# MCXA133 register map
Vendor: nxp.com; File version: 1.0
CPU: CM33 r2p0, little endian, no MPU, no FPU, VTOR, 3 interrupt priority bits
Registers are 32-bit, read-write, reset 0x0 unless marked. A register's access mark holds for its fields unless they carry their own. Offsets are from the block's base; [hi:lo] are bit positions; {n}, {i} and the like mark numbered series; 'fields as' and 'values as' point back to an identical list.

## ADC0 — ADC
Base 0x400AF000
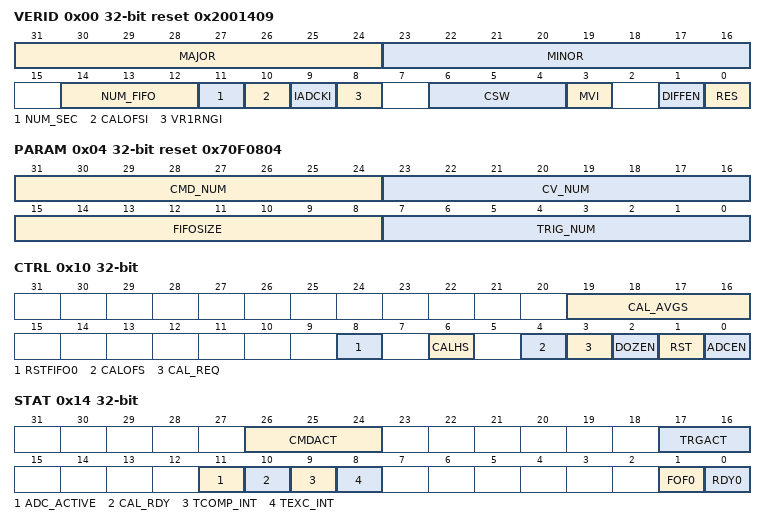
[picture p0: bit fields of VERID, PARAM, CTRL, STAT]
0x00 VERID ro reset 0x2001409 — Version ID Register
  [31:24] MAJOR — Major Version Number
  [23:16] MINOR — Minor Version Number
  [14:12] NUM_FIFO — Number of FIFOs
    0=NO_FIFO_IMPLEMENTED (N/A); 1=CNT_1 (This design supports one result FIFO.); 2=CNT_2 (This design supports two result FIFOs.); 3=CNT_3 (This design supports three result FIFOs.); 4=CNT_4 (This design supports four result FIFOs.)
  [11] NUM_SEC — Number of Single Ended Outputs Supported
    0=SINGLE_CONVERTOR (This design supports one single ended conversion at a time.); 1=DUAL_CONVERTOR (This design supports two simultaneous single ended conversions.)
  [10] CALOFSI — Calibration Function Implemented
    0=CAL_FUNCTION_NOT_AVAILABLE (Calibration Not Implemented.); 1=CAL_FUNCTION_AVAILABLE (Calibration Implemented.)
  [9] IADCKI — Internal ADC Clock Implemented
    0=INTERNAL_CLK_NOT_AVAILABLE (Internal clock source not implemented.); 1=INTERNAL_CLK_AVAILABLE (Internal clock source (and CFG[ADCKEN]) implemented.)
  [8] VR1RNGI — Voltage Reference 1 Range Control Bit Implemented
    0=REF1_FIXED_VOLTAGE_RANGE (Range control not required. CFG[VREF1RNG] is not implemented.); 1=REF1_SELECTABLE_VOLTAGE_RANGE (Range control required. CFG[VREF1RNG] is implemented.)
  [6:4] CSW — Channel Scale Width
    0=CSCALE_NOT_SUPPORTED (Channel scaling not supported.); 1=BIT_WIDTH_1 (Channel scaling supported. 1-bit CSCALE control field.); 6=BIT_WIDTH_6 (Channel scaling supported. 6-bit CSCALE control field.)
  [3] MVI — Multi Vref Implemented
    0=MULTIPLE_REF_NOT_SUPPORTED (Single voltage reference high (VREFH) input supported.); 1=MULTIPLE_REF_SUPPORTED (Multiple voltage reference high (VREFH) inputs supported.)
  [1] DIFFEN — Differential Supported
    0=DIFFERENTIAL_NOT_SUPPORTED (Differential operation not supported.); 1=DIFFERENTIAL_SUPPORTED (Differential operation supported.)
  [0] RES — Resolution
    0=MAX_13_bit (Up to 12-bit single ended resolution supported (and 13-bit differential resolution if VERID[DIFFEN] = 1b).); 1=MAX_16_bit (Up to 16-bit single ended resolution supported (and 16-bit differential resolution if VERID[DIFFEN] = 1b).)
0x04 PARAM ro reset 0x70F0804 — Parameter Register
  [31:24] CMD_NUM — Command Buffer Number
  [23:16] CV_NUM — Compare Value Number
  [15:8] FIFOSIZE — Result FIFO Depth
    1=ENTRIES_2 (Result FIFO depth = 2 dataword.); 4=ENTRIES_4 (Result FIFO depth = 4 datawords.); 8=ENTRIES_8 (Result FIFO depth = 8 datawords.); 16=ENTRIES_16 (Result FIFO depth = 16 datawords.); 32=ENTRIES_32 (Result FIFO depth = 32 datawords.); 64=ENTRIES_64 (Result FIFO depth = 64 datawords.)
  [7:0] TRIG_NUM — Trigger Number
0x10 CTRL — Control Register
  [19:16] CAL_AVGS — Auto-Calibration Averages
    0=NO_AVERAGE (Single conversion.); 1=AVERAGE_2 (2 conversions averaged.); 2=AVERAGE_4 (4 conversions averaged.); 3=AVERAGE_8 (8 conversions averaged.); 4=AVERAGE_16 (16 conversions averaged.); 5=AVERAGE_32 (32 conversions averaged.); 6=AVERAGE_64 (64 conversions averaged.); 7=AVERAGE_128 (128 conversions averaged.); 8=AVERAGE_256 (256 conversions averaged.); 9=AVERAGE_512 (512 conversions averaged.); 10=AVERAGE_1024 (1024 conversions averaged.)
  [8] RSTFIFO0 — Reset FIFO 0
    0=NO_ACTION (No effect.); 1=TRIGGER_RESET (FIFO 0 is reset.)
  [6] CALHS — High Speed Mode Trim Request
    0=NO_ACTIVE_HS_TRIM_REQUEST (No request for high speed mode trim has been made); 1=HS_TRIM_REQUEST_PENDING (Request for high speed mode trim has been made)
  [4] CALOFS — Offset Calibration Request
    0=NO_ACTIVE_OFFSET_CALIBRATION_REQUEST (No request for offset calibration has been made); 1=OFFSET_CALIBRATION_REQUEST_PENDING (Request for offset calibration function)
  [3] CAL_REQ — Auto-Calibration Request
    0=NO_CALIBRATION_REQUEST (No request for hardware calibration has been made); 1=CALIBRATION_REQUEST_PENDING (A request for hardware calibration has been made)
  [2] DOZEN — Doze Enable
    0=ENABLED (ADC is enabled in low power mode.); 1=DISABLED (ADC is disabled in low power mode.)
  [1] RST — Software Reset
    0=RELEASED_FROM_RESET (ADC logic is not reset.); 1=HELD_IN_RESET (ADC logic is reset.)
  [0] ADCEN — ADC Enable
    0=DISABLED (ADC is disabled.); 1=ENABLED (ADC is enabled.)
0x14 STAT — Status Register
  [26:24] CMDACT ro — Command Active
    0=NO_COMMAND_ACTIVE (No command is currently in progress.); 1=COMMAND_1 (Command 1 currently being executed.); 2=COMMAND_2 (Command 2 currently being executed.); {v}=COMMAND_x_{v} (Associated command number is currently being executed.) (v=3..7)
  [17:16] TRGACT ro — Trigger Active
    {v}=TRIG_{v} (Command (sequence) associated with Trigger {v} currently being executed.) (v=0..3)
  [11] ADC_ACTIVE ro
    0=NOT_ACTIVE (The ADC is IDLE. There are no pending triggers to service and no active commands are being processed.); 1=BUSY (The ADC is processing a conversion, running through the power up delay, or servicing a trigger.)
  [10] CAL_RDY ro — Calibration Ready
    0=NOT_SET (Calibration is incomplete or hasn't been ran.); 1=HARDWARE_CAL_STEP_COMPLETED (The ADC is calibrated.)
  [9] TCOMP_INT write-1-clears — Interrupt Flag For Trigger Completion
    0=FLAG_CLEAR (Either IE[TCOMP_IE] is set to 0, or no trigger sequences have run to completion.); 1=COMPLETION_DETECTED (Trigger sequence has been completed and all data is stored in the associated FIFO.)
  [8] TEXC_INT write-1-clears — Interrupt Flag For High Priority Trigger Exception
    0=NO_EXCEPTION (No trigger exceptions have occurred.); 1=EXCEPTION_DETECTED (A trigger exception has occurred and is pending acknowledgement.)
  [1] FOF0 write-1-clears — Result FIFO 0 Overflow Flag
    0=NO_OVERFLOW (No result FIFO 0 overflow has occurred since the last time the flag was cleared.); 1=OVERFLOW_DETECTED (At least one result FIFO 0 overflow has occurred since the last time the flag was cleared.)
  [0] RDY0 ro — Result FIFO 0 Ready Flag
    0=BELOW_THRESHOLD (Result FIFO 0 data level not above watermark level.); 1=ABOVE_THRESHOLD (Result FIFO 0 holding data above watermark level.)
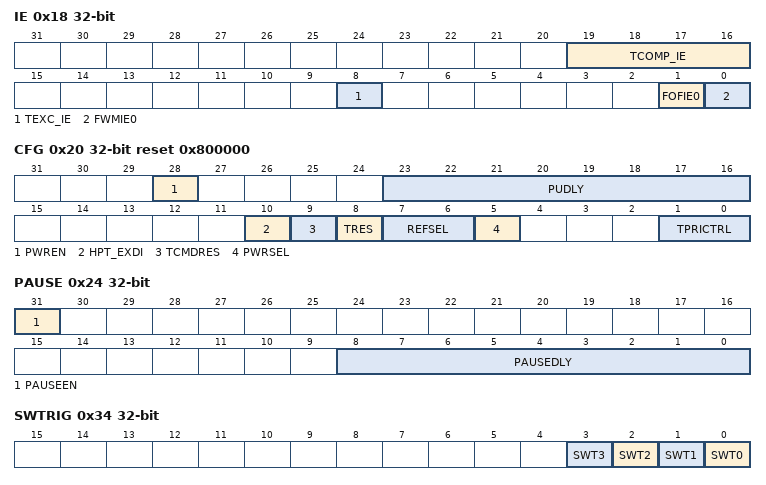
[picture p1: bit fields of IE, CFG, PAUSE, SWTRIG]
0x18 IE — Interrupt Enable Register
  [19:16] TCOMP_IE — Trigger Completion Interrupt Enable
    0=DISABLED (Trigger completion interrupts are disabled.); 1=TRIGGER_0_COMPLETE_ENABLED (Trigger completion interrupts are enabled for trigger source 0 only.); 2=TRIGGER_1_COMPLETE_ENABLED (Trigger completion interrupts are enabled for trigger source 1 only.); {v}=TRIGGER_x_COMPLETE_ENABLED_{v} (Associated trigger completion interrupts are enabled.) (v=3..14); 15=ALL_TRIGGER_COMPLETES_ENABLED (Trigger completion interrupts are enabled for every trigger source.)
  [8] TEXC_IE — Trigger Exception Interrupt Enable
    0=DISABLED (Trigger exception interrupts are disabled.); 1=ENABLED (Trigger exception interrupts are enabled.)
  [1] FOFIE0 — Result FIFO 0 Overflow Interrupt Enable
    0=DISABLED (FIFO 0 overflow interrupts are not enabled.); 1=ENABLED (FIFO 0 overflow interrupts are enabled.)
  [0] FWMIE0 — FIFO 0 Watermark Interrupt Enable
    0=DISABLED (FIFO 0 watermark interrupts are not enabled.); 1=ENABLED (FIFO 0 watermark interrupts are enabled.)
0x1C DE — DMA Enable Register
  [0] FWMDE0 — FIFO 0 Watermark DMA Enable
    0=DISABLED (DMA request disabled.); 1=ENABLED (DMA request enabled.)
0x20 CFG reset 0x800000 — Configuration Register
  [28] PWREN — ADC Analog Pre-Enable
    0=NOT_PRE_ENABLED (ADC analog circuits are only enabled while conversions are active. Performance is affected due to analog startup delays.); 1=PRE_ENABLED (ADC analog circuits are pre-enabled and ready to execute conversions without startup delays (at the cost of higher DC current consumption). Note that a single power up delay (CFG[PUDLY]) is executed immediately once PWREN is set, and any detected trigger does not begin ADC operation until the power up delay time has passed. After this initial delay expires the analog remains pre-enabled and no additional delays are executed.)
  [23:16] PUDLY — Power Up Delay
  [10] HPT_EXDI — High Priority Trigger Exception Disable
    0=ENABLED (High priority trigger exceptions are enabled.); 1=DISABLED (High priority trigger exceptions are disabled.)
  [9] TCMDRES — Trigger Command Resume
    0=DISABLED (Trigger sequences interrupted by a high priority trigger exception is automatically restarted.); 1=ENABLED (Trigger sequences interrupted by a high priority trigger exception is resumed from the command executing before the exception.)
  [8] TRES — Trigger Resume Enable
    0=DISABLED (Trigger sequences interrupted by a high priority trigger exception are not automatically resumed or restarted.); 1=ENABLED (Trigger sequences interrupted by a high priority trigger exception are automatically resumed or restarted.)
  [7:6] REFSEL — Voltage Reference Selection
    0=OPTION_1 ((Default) Option 1 setting.); 1=OPTION_2 (Option 2 setting.); 2=OPTION_3 (Option 3 setting.)
  [5] PWRSEL — Power Configuration Select
    0=LOWEST (Low power); 1=HIGHEST (High power)
  [1:0] TPRICTRL — ADC Trigger Priority Control
    0=ABORT_CURRENT_ON_PRIORITY (If a higher priority trigger is detected during command processing, the current conversion is aborted and the new command specified by the trigger is started.); 1=FINISH_CURRENT_ON_PRIORITY (If a higher priority trigger is received during command processing, the current command is stopped after completing the current conversion. If averaging is enabled, the averaging loop will be completed. However, CMDHa[LOOP] will be ignored and the higher priority trigger will be serviced.); 2=FINISH_SEQUENCE_ON_PRIORITY (If a higher priority trigger is received during command processing, the current command will be completed (averaging, looping, compare) before servicing the higher priority trigger.)
0x24 PAUSE
  [31] PAUSEEN — PAUSE Option Enable
    0=DISABLED (Pause operation disabled); 1=ENABLED (Pause operation enabled)
  [8:0] PAUSEDLY — Pause Delay
0x34 SWTRIG — Software Trigger Register
  [n] SWT{n} (n=0..3) — Software Trigger {n} Event
    0=NO_TRIGGER (No trigger {n} event generated.); 1=INITIATE_TRIGGER_{n} (Trigger {n} event generated.)
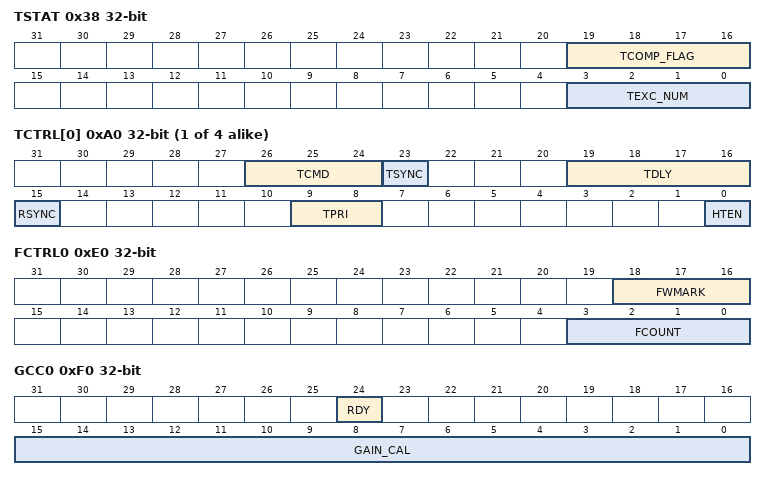
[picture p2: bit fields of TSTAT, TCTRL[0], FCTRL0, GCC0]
0x38 TSTAT write-1-clears — Trigger Status Register
  [19:16] TCOMP_FLAG write-1-clears — Trigger Completion Flag
    0=NO_TRIGGER (No triggers have been completed. Trigger completion interrupts are disabled.); 1=BIT0_MEANS_TRIGGER_0_COMPLETED (Trigger 0 has been completed and trigger 0 has enabled completion interrupts.); 2=BIT1_MEANS_TRIGGER_1_COMPLETED (Trigger 1 has been completed and trigger 1 has enabled completion interrupts.); {v}=SET_BITS_INDICATE_TRIGGER_x_COMPLETED_{v} (Associated trigger sequence has completed and has enabled completion interrupts.) (v=3..14); 15=ALL_BITS_SET_INDICATE_ALL_TRIGGERS_COMPLETED (Every trigger sequence has been completed and every trigger has enabled completion interrupts.)
  [3:0] TEXC_NUM write-1-clears — Trigger Exception Number
    0=NO_EXCEPTIONS (No triggers have been interrupted by a high priority exception. Or CFG[TRES] = 1.); 1=BIT0_MEANS_TRIGGER_0_INTERRUPTED (Trigger 0 has been interrupted by a high priority exception.); 2=BIT1_MEANS_TRIGGER_1_INTERRUPTED (Trigger 1 has been interrupted by a high priority exception.); {v}=SET_BITS_INDICATE_TRIGGER_x_INTERRUPTED_{v} (Associated trigger sequence has interrupted by a high priority exception.) (v=3..14); 15=ALL_BITS_SET_INDICATE_ALL_TRIGGERS_INTERRUPTED (Every trigger sequence has been interrupted by a high priority exception.)
0x40 OFSTRIM — Offset Trim Register
  [9:0] OFSTRIM — Trim for Offset
0x48 HSTRIM — High Speed Trim Register
  [4:0] HSTRIM — Trim for High Speed Conversions
{0xA0+4i} TCTRL[{i}] (i=0..3) — Trigger Control Register
  [26:24] TCMD — Trigger Command Select
    0=NOT_VALID (Not a valid selection from the command buffer. Trigger event is ignored.); 1=EXECUTE_CMD1 (CMD1 is executed); {v}=EXECUTE_CORRESPONDING_CMD_{v} (Corresponding CMD is executed) (v=2..6); 7=EXECUTE_CMD7 (CMD7 is executed)
  [23] TSYNC — Trigger Synchronous Select
  [19:16] TDLY — Trigger Delay Select
  [15] RSYNC — Trigger Resync
  [9:8] TPRI — Trigger Priority Setting
    0=HIGHEST_PRIORITY (Set to highest priority, Level 1); 1=CORRESPONDING_LOWER_PRIORITY_1 (Set to corresponding priority level); 2=CORRESPONDING_LOWER_PRIORITY_2 (Set to corresponding priority level); 3=LOWEST_PRIORITY (Set to lowest priority, Level 4)
  [0] HTEN — Trigger Enable
    0=DISABLED (Hardware trigger source disabled); 1=ENABLED (Hardware trigger source enabled)
0xE0 FCTRL0 — FIFO Control Register
  [18:16] FWMARK — Watermark Level Selection
  [3:0] FCOUNT ro — Result FIFO Counter
0xF0 GCC0 ro — Gain Calibration Control
  [24] RDY — Gain Calibration Value Valid
    0=GAIN_CAL_NOT_VALID (The GAIN_CAL value is invalid. Run the hardware calibration routine for this value to be set.); 1=HARDWARE_CAL_ROUTINE_COMPLETED (The GAIN_CAL value is valid. GAIN_CAL should be used by software to derive GCRa[GCALR].)
  [15:0] GAIN_CAL — Gain Calibration Value
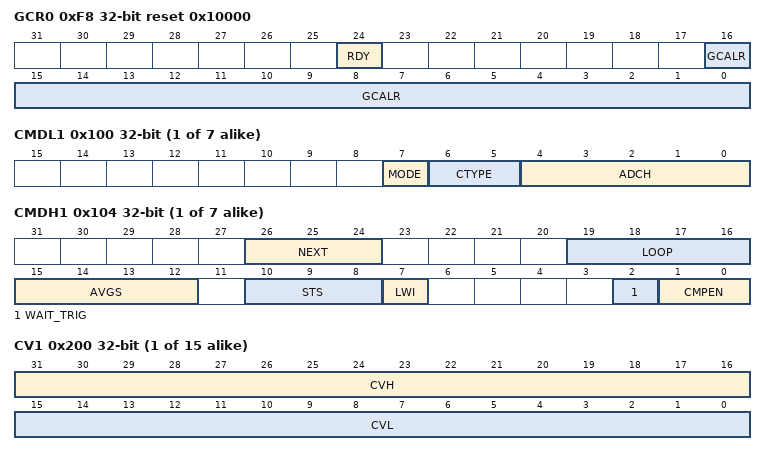
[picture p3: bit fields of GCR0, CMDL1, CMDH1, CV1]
0xF8 GCR0 reset 0x10000 — Gain Calculation Result
  [24] RDY — Gain Calculation Ready
    0=NOT_VALID (The GCALR value is invalid.); 1=VALID (The GCALR value is valid.)
  [16:0] GCALR — Gain Calculation Result
{0xF8+8i} CMDL{i} (i=1..7) — Command Low Buffer Register
  [7] MODE — Select Resolution of Conversions
    0=DATA_12_BITS (Standard resolution. Single-ended 12-bit conversion.); 1=DATA_16_BITS (High resolution. Single-ended 16-bit conversion.)
  [6:5] CTYPE ro — Conversion Type
    0=SINGLE_ENDED_A_SIDE_CHANNEL (Single-Ended Mode. Only A side channel is converted.)
  [4:0] ADCH — Input Channel Select
    {v}=SELECT_CH{v} (Select CH{v}A.) (v=0..3); {v}=SELECT_CORRESPONDING_CHANNEL_{v} (Select corresponding channel CHnA.) (v=4..13); {v}=SELECT_CORRESPONDING_CHANNEL_{v} (Select corresponding channel CHnA.) (v=24..29); 30=SELECT_CH30 (Select CH30A.); 31=SELECT_CH31 (Select CH31A.)
{0xFC+8i} CMDH{i} (i=1..7) — Command High Buffer Register
  [26:24] NEXT — Next Command Select
    0=NO_NEXT_CMD_TERMINATE_ON_FINISH (No next command defined. Terminate conversions at completion of current command. If lower priority trigger pending, begin command associated with lower priority trigger.); 1=DO_CMD1_NEXT (Select CMD1 command buffer register as next command.); {v}=DO_CORRESPONDING_CMD_NEXT_{v} (Select corresponding CMD command buffer register as next command) (v=2..6); 7=DO_CMD7_NEXT (Select CMD7 command buffer register as next command.)
  [19:16] LOOP — Loop Count Select
    0=CMD_EXEC_1x (Looping not enabled. Command executes 1 time.); 1=CMD_EXEC_2x (Loop 1 time. Command executes 2 times.); 2=CMD_EXEC_3x (Loop 2 times. Command executes 3 times.); {v}=CMD_EXECUTES_CORRESPONDING_TIMES_{v} (Loop corresponding number of times. Command executes LOOP+1 times.) (v=3..14); 15=CMD_EXEC_15x (Loop 15 times. Command executes 16 times.)
  [15:12] AVGS — Hardware Average Select
    values as CTRL.CAL_AVGS
  [10:8] STS — Sample Time Select
    0=SAMPLE_3p5 (Minimum sample time of 3.5 ADCK cycles.); 1=SAMPLE_5p5 (3.5 + 21 ADCK cycles; 5.5 ADCK cycles total sample time.); 2=SAMPLE_7p5 (3.5 + 22 ADCK cycles; 7.5 ADCK cycles total sample time.); 3=SAMPLE_11p5 (3.5 + 23 ADCK cycles; 11.5 ADCK cycles total sample time.); 4=SAMPLE_19p5 (3.5 + 24 ADCK cycles; 19.5 ADCK cycles total sample time.); 5=SAMPLE_35p5 (3.5 + 25 ADCK cycles; 35.5 ADCK cycles total sample time.); 6=SAMPLE_67p5 (3.5 + 26 ADCK cycles; 67.5 ADCK cycles total sample time.); 7=SAMPLE_131p5 (3.5 + 27 ADCK cycles; 131.5 ADCK cycles total sample time.)
  [7] LWI — Loop with Increment
    0=DISABLED (Auto channel increment disabled); 1=ENABLED (Auto channel increment enabled)
  [2] WAIT_TRIG — Wait for Trigger Assertion before Execution.
    0=DISABLED (This command will be automatically executed.); 1=ENABLED (The active trigger must be asserted again before executing this command.)
  [1:0] CMPEN — Compare Function Enable
    0=DISABLED_ALWAYS_STORE_RESULT (Compare disabled.); 2=COMPARE_RESULT_STORE_IF_TRUE (Compare enabled. Store on true.); 3=COMPARE_RESULT_KEEP_CONVERTING_UNTIL_TRUE_STORE_IF_TRUE (Compare enabled. Repeat channel acquisition (sample/convert/compare) until true.)
{0x1FC+4i} CV{i} (i=1..15) — Compare Value Register
  [31:16] CVH — Compare Value High
  [15:0] CVL — Compare Value Low
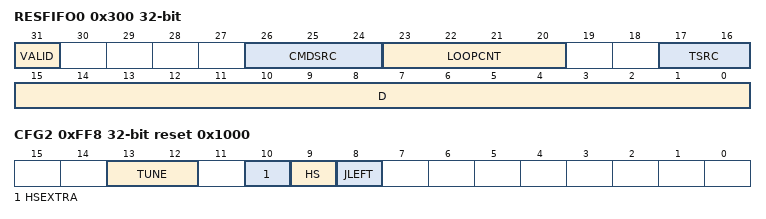
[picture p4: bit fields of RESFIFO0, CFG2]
0x300 RESFIFO0 ro — Data Result FIFO Register
  [31] VALID — FIFO Entry is Valid
    0=NOT_VALID (FIFO is empty. Discard any read from RESFIFO.); 1=VALID (FIFO record read from RESFIFO is valid.)
  [26:24] CMDSRC — Command Buffer Source
    0=NOT_VALID (Not a valid value CMDSRC value for a dataword in RESFIFO. 0x0 is only found in initial FIFO state prior to an ADC conversion result dataword being stored to a RESFIFO buffer.); 1=CMD1 (CMD1 buffer used as control settings for this conversion.); {v}=CORRESPONDING_CMD_{v} (Corresponding command buffer used as control settings for this conversion.) (v=2..6); 7=CMD7 (CMD7 buffer used as control settings for this conversion.)
  [23:20] LOOPCNT — Loop Count Value
    0=RESULT_1 (Result is from initial conversion in command.); 1=RESULT_2 (Result is from second conversion in command.); {v}=CORRESPONDING_RESULT_{v} (Result is from LOOPCNT+1 conversion in command.) (v=2..14); 15=RESULT_16 (Result is from 16th conversion in command.)
  [17:16] TSRC — Trigger Source
    0=TRIGGER_0 (Trigger source 0 initiated this conversion.); 1=TRIGGER_1 (Trigger source 1 initiated this conversion.); 2=CORRESPONDING_TRIGGER_2 (Corresponding trigger source initiated this conversion.); 3=TRIGGER_3 (Trigger source 3 initiated this conversion.)
  [15:0] D — Data Result
{0x400+4i} CAL_GAR[{i}] (i=0..32) — Calibration General A-Side Registers
  [15:0] CAL_GAR_VAL — Calibration General A Side Register Element
0xFF8 CFG2 reset 0x1000 — Configuration 2 Register
  [13:12] TUNE — Tune Mode register
  [10] HSEXTRA — High Speed Extra register
    0=No extra cycle added; 1=Extra cycle added
  [9] HS — High Speed Enable register
    0=DISABLED (High speed conversion mode disabled); 1=ENABLED (High speed conversion mode enabled)
  [8] JLEFT — Justified Left Enable register
